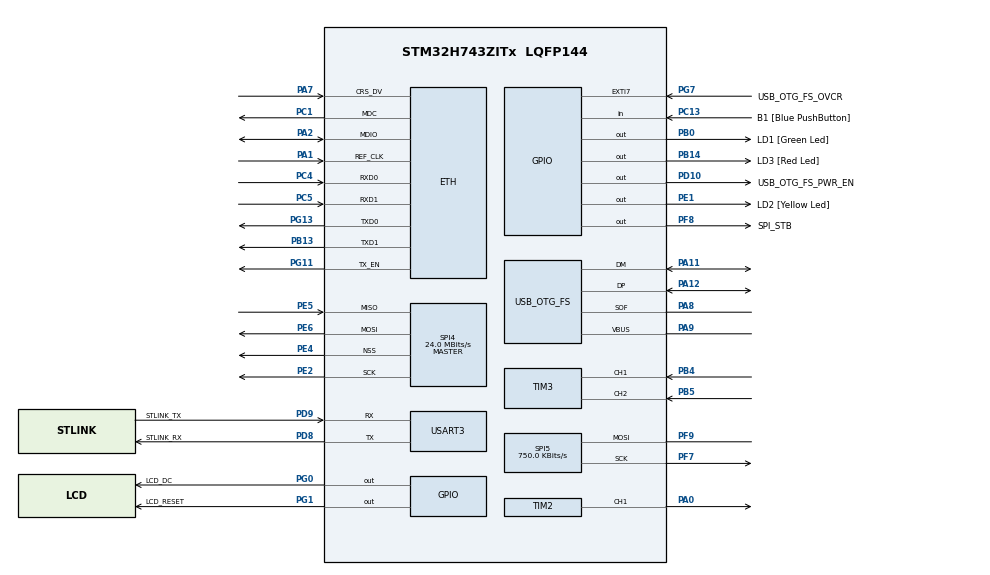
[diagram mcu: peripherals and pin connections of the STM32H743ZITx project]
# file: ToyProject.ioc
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CORTEX_M7.CPU_DCache=Enabled
CORTEX_M7.CPU_ICache=Enabled
CORTEX_M7.default_mode_Activation=0
Dma.Request0=SPI5_TX
Dma.SPI5_TX.0.Direction=DMA_MEMORY_TO_PERIPH
Dma.SPI5_TX.0.EventEnable=DISABLE
Dma.SPI5_TX.0.FIFOMode=DMA_FIFOMODE_ENABLE
Dma.SPI5_TX.0.FIFOThreshold=DMA_FIFO_THRESHOLD_FULL
Dma.SPI5_TX.0.Instance=DMA1_Stream0
Dma.SPI5_TX.0.MemBurst=DMA_MBURST_SINGLE
Dma.SPI5_TX.0.MemDataAlignment=DMA_MDATAALIGN_WORD
Dma.SPI5_TX.0.MemInc=DMA_MINC_ENABLE
Dma.SPI5_TX.0.Mode=DMA_NORMAL
Dma.SPI5_TX.0.PeriphBurst=DMA_PBURST_SINGLE
Dma.SPI5_TX.0.PeriphDataAlignment=DMA_PDATAALIGN_WORD
Dma.SPI5_TX.0.PeriphInc=DMA_PINC_DISABLE
Dma.SPI5_TX.0.Polarity=HAL_DMAMUX_REQ_GEN_RISING
Dma.SPI5_TX.0.Priority=DMA_PRIORITY_LOW
Dma.SPI5_TX.0.RequestNumber=1
Dma.SPI5_TX.0.SignalID=NONE
Dma.SPI5_TX.0.SyncEnable=DISABLE
Dma.SPI5_TX.0.SyncPolarity=HAL_DMAMUX_SYNC_NO_EVENT
Dma.SPI5_TX.0.SyncRequestNumber=1
Dma.SPI5_TX.0.SyncSignalID=NONE
ETH.MediaInterface=HAL_ETH_RMII_MODE
FREERTOS.Tasks01=defaultTask,0,128,StartDefaultTask,Default,NULL,Dynamic,NULL,NULL
FREERTOS.configENABLE_FPU=0
FREERTOS.configUSE_NEWLIB_REENTRANT=0
FREERTOS.configUSE_PREEMPTION=1
Mcu.Family=STM32H7
Mcu.Name=STM32H743ZITx
Mcu.Package=LQFP144
NVIC.DMA1_Stream0_IRQn=true\:5\:0\:false\:false\:true\:true\:false\:true\:true
NVIC.PriorityGroup=NVIC_PRIORITYGROUP_4
NVIC.SPI4_IRQn=true\:5\:0\:false\:false\:true\:true\:true\:true\:true
NVIC.SPI5_IRQn=true\:5\:0\:false\:false\:true\:true\:true\:true\:true
NVIC.TIM7_IRQn=true\:15\:0\:false\:false\:true\:false\:false\:true\:true
NVIC.TimeBase=TIM7_IRQn
NVIC.TimeBaseIP=TIM7
PA0.Signal=S_TIM2_CH1_ETR
PA1.Mode=RMII
PA1.Signal=ETH_REF_CLK
PA11.Mode=Device_Only
PA11.Signal=USB_OTG_FS_DM
PA12.Mode=Device_Only
PA12.Signal=USB_OTG_FS_DP
PA2.Mode=RMII
PA2.Signal=ETH_MDIO
PA7.Mode=RMII
PA7.Signal=ETH_CRS_DV
PA8.Mode=Activate_SOF_FS
PA8.Signal=USB_OTG_FS_SOF
PA9.Mode=Activate_VBUS
PA9.Signal=USB_OTG_FS_VBUS
PB0.GPIO_Label=LD1 [Green Led]
PB0.Signal=GPIO_Output
PB13.Mode=RMII
PB13.Signal=ETH_TXD1
PB14.GPIO_Label=LD3 [Red Led]
PB14.Signal=GPIO_Output
PB4\ (NJTRST).Signal=S_TIM3_CH1
PB5.Signal=S_TIM3_CH2
PC1.Mode=RMII
PC1.Signal=ETH_MDC
PC13.GPIO_Label=B1 [Blue PushButton]
PC13.Signal=GPIO_Input
PC14-OSC32_IN\ (OSC32_IN).Mode=LSE-External-Oscillator
PC14-OSC32_IN\ (OSC32_IN).Signal=RCC_OSC32_IN
PC15-OSC32_OUT\ (OSC32_OUT).Mode=LSE-External-Oscillator
PC15-OSC32_OUT\ (OSC32_OUT).Signal=RCC_OSC32_OUT
PC4.Mode=RMII
PC4.Signal=ETH_RXD0
PC5.Mode=RMII
PC5.Signal=ETH_RXD1
PD10.GPIO_Label=USB_OTG_FS_PWR_EN
PD10.Signal=GPIO_Output
PD8.GPIO_Label=STLINK_RX
PD8.Mode=Asynchronous
PD8.Signal=USART3_TX
PD9.GPIO_Label=STLINK_TX
PD9.Mode=Asynchronous
PD9.Signal=USART3_RX
PE1.GPIO_Label=LD2 [Yellow Led]
PE1.Signal=GPIO_Output
PE2.Mode=Full_Duplex_Master
PE2.Signal=SPI4_SCK
PE4.Mode=NSS_Signal_Hard_Output
PE4.Signal=SPI4_NSS
PE5.Mode=Full_Duplex_Master
PE5.Signal=SPI4_MISO
PE6.Mode=Full_Duplex_Master
PE6.Signal=SPI4_MOSI
PF7.Mode=Simplex_Bidirectional_Master
PF7.Signal=SPI5_SCK
PF8.GPIO_Label=SPI_STB
PF8.Signal=GPIO_Output
PF9.Mode=Simplex_Bidirectional_Master
PF9.Signal=SPI5_MOSI
PG0.GPIO_Label=LCD_DC
PG0.Signal=GPIO_Output
PG1.GPIO_Label=LCD_RESET
PG1.Signal=GPIO_Output
PG11.Mode=RMII
PG11.Signal=ETH_TX_EN
PG13.Mode=RMII
PG13.Signal=ETH_TXD0
PG7.GPIO_Label=USB_OTG_FS_OVCR
PG7.Signal=GPXTI7
PH0-OSC_IN\ (PH0).Mode=HSE-External-Clock-Source
PH0-OSC_IN\ (PH0).Signal=RCC_OSC_IN
PH1-OSC_OUT\ (PH1).Signal=RCC_OSC_OUT
ProjectManager.HeapSize=0x200
ProjectManager.StackSize=0x400
ProjectManager.TargetToolchain=EWARM V8.50
RCC.ADCFreq_Value=480000000
RCC.APB1Freq_Value=120000000
RCC.APB2Freq_Value=120000000
RCC.APB3Freq_Value=120000000
RCC.APB4Freq_Value=120000000
RCC.CortexFreq_Value=480000000
RCC.D1PPRE=RCC_APB3_DIV2
RCC.D2PPRE1=RCC_APB1_DIV2
RCC.D2PPRE2=RCC_APB2_DIV2
RCC.D3PPRE=RCC_APB4_DIV2
RCC.DIVM1=1
RCC.DIVM2=1
RCC.DIVM3=1
RCC.DIVN1=120
RCC.DIVN2=120
RCC.DIVN3=120
RCC.DIVQ1=20
RCC.DIVQ2=20
RCC.HCLKFreq_Value=240000000
RCC.HPRE=RCC_HCLK_DIV2
RCC.HSE_VALUE=8000000
RCC.PLLFRACN=0
RCC.PWR_Regulator_Voltage_Scale=PWR_REGULATOR_VOLTAGE_SCALE0
RCC.RTCClockSelection=RCC_RTCCLKSOURCE_LSE
RCC.SPI6CLockSelection=RCC_SPI6CLKSOURCE_PLL2
RCC.SYSCLKFreq_VALUE=480000000
RCC.SYSCLKSource=RCC_SYSCLKSOURCE_PLLCLK
RCC.Spi45ClockSelection=RCC_SPI45CLKSOURCE_PLL2
RCC.USBFreq_Value=48000000
SH.S_TIM2_CH1_ETR.0=TIM2_CH1,PWM Generation1 CH1
SH.S_TIM3_CH1.0=TIM3_CH1,Encoder_Interface
SH.S_TIM3_CH2.0=TIM3_CH2,Encoder_Interface
SPI4.CalculateBaudRate=24.0 MBits/s
SPI4.DataSize=SPI_DATASIZE_8BIT
SPI4.Direction=SPI_DIRECTION_2LINES
SPI4.Mode=SPI_MODE_MASTER
SPI4.VirtualNSS=VM_NSSHARD
SPI4.VirtualType=VM_MASTER
SPI5.BaudRatePrescaler=SPI_BAUDRATEPRESCALER_64
SPI5.CalculateBaudRate=750.0 KBits/s
SPI5.DataSize=SPI_DATASIZE_8BIT
SPI5.Direction=SPI_DIRECTION_1LINE
SPI5.FirstBit=SPI_FIRSTBIT_LSB
SPI5.Mode=SPI_MODE_MASTER
SPI5.VirtualType=VM_MASTER
TIM2.Channel-PWM\ Generation1\ CH1=TIM_CHANNEL_1
TIM2.Period=100 - 1
TIM2.Prescaler=240000 - 1 /* 240MHz / 240000 \= 1KHz, 1ms */
USART3.VirtualMode-Asynchronous=VM_ASYNC
USB_OTG_FS.VirtualMode=Device_Only
VP_CRC_VS_CRC.Mode=CRC_Activate
VP_FREERTOS_VS_CMSIS_V1.Mode=CMSIS_V1
VP_RTC_VS_RTC_Activate.Mode=RTC_Enabled
VP_RTC_VS_RTC_Calendar.Mode=RTC_Calendar
VP_SYS_VS_tim7.Mode=TIM7
VP_TIM2_VS_ClockSourceINT.Mode=Internal
board=NUCLEO-H743ZI2

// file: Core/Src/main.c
/* USER CODE BEGIN Header */
/**
  ******************************************************************************
  * @file           : main.c
  * @brief          : Main program body
  ******************************************************************************
  * @attention
  *
  * Copyright (c) 2025 STMicroelectronics.
  * All rights reserved.
  *
  * This software is licensed under terms that can be found in the LICENSE file
  * in the root directory of this software component.
  * If no LICENSE file comes with this software, it is provided AS-IS.
  *
  ******************************************************************************
  */
/* USER CODE END Header */
#include "main.h"
#include "cmsis_os.h"
#include "crc.h"
#include "dma.h"
#include "eth.h"
#include "rtc.h"
#include "spi.h"
#include "tim.h"
#include "usart.h"
#include "usb_otg.h"
#include "gpio.h"

/* USER CODE BEGIN Includes */
#include "sys_main.h"
#include "version.h"
/* USER CODE END Includes */

void SystemClock_Config(void);
void PeriphCommonClock_Config(void);
void MX_FREERTOS_Init(void);

int main(void)
{
/* Enable the CPU Cache */

  /* Enable I-Cache---------------------------------------------------------*/
  SCB_EnableICache();

  /* Enable D-Cache---------------------------------------------------------*/
  SCB_EnableDCache();

  /* MCU Configuration--------------------------------------------------------*/

  /* Reset of all peripherals, Initializes the Flash interface and the Systick. */
  HAL_Init();

  /* Configure the system clock */
  SystemClock_Config();

/* Configure the peripherals common clocks */
  PeriphCommonClock_Config();

  /* Initialize all configured peripherals */
  MX_GPIO_Init();
  MX_DMA_Init();
  MX_RTC_Init();
  MX_USART3_UART_Init();
  MX_TIM2_Init();
  MX_CRC_Init();
  MX_ETH_Init();
  MX_SPI4_Init();
  MX_SPI5_Init();
  MX_USB_OTG_FS_PCD_Init();
  MX_TIM3_Init();
  /* USER CODE BEGIN 2 */
  User_SystemInit();
  vTaskStartScheduler();
#if 0
  /* USER CODE END 2 */

  /* Call init function for freertos objects (in freertos.c) */
  MX_FREERTOS_Init();

  /* Start scheduler */
  osKernelStart();

  /* We should never get here as control is now taken by the scheduler */
  /* Infinite loop */
  /* USER CODE BEGIN WHILE */
#endif
  while (1)
  {
    /* USER CODE END WHILE */

  }
}

void SystemClock_Config(void)
{
  RCC_OscInitTypeDef RCC_OscInitStruct = {0};
  RCC_ClkInitTypeDef RCC_ClkInitStruct = {0};

  /** Supply configuration update enable
  */
  HAL_PWREx_ConfigSupply(PWR_LDO_SUPPLY);

  /** Configure the main internal regulator output voltage
  */
  __HAL_PWR_VOLTAGESCALING_CONFIG(PWR_REGULATOR_VOLTAGE_SCALE1);

  while(!__HAL_PWR_GET_FLAG(PWR_FLAG_VOSRDY)) {}

  __HAL_RCC_SYSCFG_CLK_ENABLE();
  __HAL_PWR_VOLTAGESCALING_CONFIG(PWR_REGULATOR_VOLTAGE_SCALE0);

  while(!__HAL_PWR_GET_FLAG(PWR_FLAG_VOSRDY)) {}

  /** Configure LSE Drive Capability
  */
  HAL_PWR_EnableBkUpAccess();
  __HAL_RCC_LSEDRIVE_CONFIG(RCC_LSEDRIVE_LOW);

  /** Initializes the RCC Oscillators according to the specified parameters
  * in the RCC_OscInitTypeDef structure.
  */
  RCC_OscInitStruct.OscillatorType = RCC_OSCILLATORTYPE_HSE|RCC_OSCILLATORTYPE_LSE;
  RCC_OscInitStruct.HSEState = RCC_HSE_BYPASS;
  RCC_OscInitStruct.LSEState = RCC_LSE_ON;
  RCC_OscInitStruct.PLL.PLLState = RCC_PLL_ON;
  RCC_OscInitStruct.PLL.PLLSource = RCC_PLLSOURCE_HSE;
  RCC_OscInitStruct.PLL.PLLM = 1;
  RCC_OscInitStruct.PLL.PLLN = 120;
  RCC_OscInitStruct.PLL.PLLP = 2;
  RCC_OscInitStruct.PLL.PLLQ = 20;
  RCC_OscInitStruct.PLL.PLLR = 2;
  RCC_OscInitStruct.PLL.PLLRGE = RCC_PLL1VCIRANGE_3;
  RCC_OscInitStruct.PLL.PLLVCOSEL = RCC_PLL1VCOWIDE;
  RCC_OscInitStruct.PLL.PLLFRACN = 0;
  if (HAL_RCC_OscConfig(&RCC_OscInitStruct) != HAL_OK)
  {
    Error_Handler();
  }

  /** Initializes the CPU, AHB and APB buses clocks
  */
  RCC_ClkInitStruct.ClockType = RCC_CLOCKTYPE_HCLK|RCC_CLOCKTYPE_SYSCLK
                              |RCC_CLOCKTYPE_PCLK1|RCC_CLOCKTYPE_PCLK2
                              |RCC_CLOCKTYPE_D3PCLK1|RCC_CLOCKTYPE_D1PCLK1;
  RCC_ClkInitStruct.SYSCLKSource = RCC_SYSCLKSOURCE_PLLCLK;
  RCC_ClkInitStruct.SYSCLKDivider = RCC_SYSCLK_DIV1;
  RCC_ClkInitStruct.AHBCLKDivider = RCC_HCLK_DIV2;
  RCC_ClkInitStruct.APB3CLKDivider = RCC_APB3_DIV2;
  RCC_ClkInitStruct.APB1CLKDivider = RCC_APB1_DIV2;
  RCC_ClkInitStruct.APB2CLKDivider = RCC_APB2_DIV2;
  RCC_ClkInitStruct.APB4CLKDivider = RCC_APB4_DIV2;

  if (HAL_RCC_ClockConfig(&RCC_ClkInitStruct, FLASH_LATENCY_4) != HAL_OK)
  {
    Error_Handler();
  }
}

void PeriphCommonClock_Config(void)
{
  RCC_PeriphCLKInitTypeDef PeriphClkInitStruct = {0};

  /** Initializes the peripherals clock
  */
  PeriphClkInitStruct.PeriphClockSelection = RCC_PERIPHCLK_SPI4|RCC_PERIPHCLK_SPI5;
  PeriphClkInitStruct.PLL2.PLL2M = 1;
  PeriphClkInitStruct.PLL2.PLL2N = 120;
  PeriphClkInitStruct.PLL2.PLL2P = 2;
  PeriphClkInitStruct.PLL2.PLL2Q = 20;
  PeriphClkInitStruct.PLL2.PLL2R = 2;
  PeriphClkInitStruct.PLL2.PLL2RGE = RCC_PLL2VCIRANGE_3;
  PeriphClkInitStruct.PLL2.PLL2VCOSEL = RCC_PLL2VCOWIDE;
  PeriphClkInitStruct.PLL2.PLL2FRACN = 0;
  PeriphClkInitStruct.Spi45ClockSelection = RCC_SPI45CLKSOURCE_PLL2;
  if (HAL_RCCEx_PeriphCLKConfig(&PeriphClkInitStruct) != HAL_OK)
  {
    Error_Handler();
  }
}

void HAL_TIM_PeriodElapsedCallback(TIM_HandleTypeDef *htim)
{
  if (htim->Instance == TIM7) {
    HAL_IncTick();
  }
}

void Error_Handler(void)
{
  __disable_irq();
  while (1)
  {
  }
}

#ifdef  USE_FULL_ASSERT
/**
  * @brief  Reports the name of the source file and the source line number
  *         where the assert_param error has occurred.
  * @param  file: pointer to the source file name
  * @param  line: assert_param error line source number
  * @retval None
  */
void assert_failed(uint8_t *file, uint32_t line)
{
  /* USER CODE BEGIN 6 */
  // 1. ?��버거�?? ?��결되?�� ?��?���?? ?��기서 멈춤 (BKPT 명령?��)
  __asm("BKPT #0");

  // 2. 로그 출력 (printf�?? ?��?��?��?�� ?��?���??)
  // printf("Assert Failed! File: %s, Line: %lu\r\n", file, line);

  /* User can add his own implementation to report the file name and line number,
     ex: printf("Wrong parameters value: file %s on line %d\r\n", file, line) */
  /* USER CODE END 6 */
}
#endif /* USE_FULL_ASSERT */
